VERSION "1"

NS_ :

BS_:

BU_: BATTERY BODY

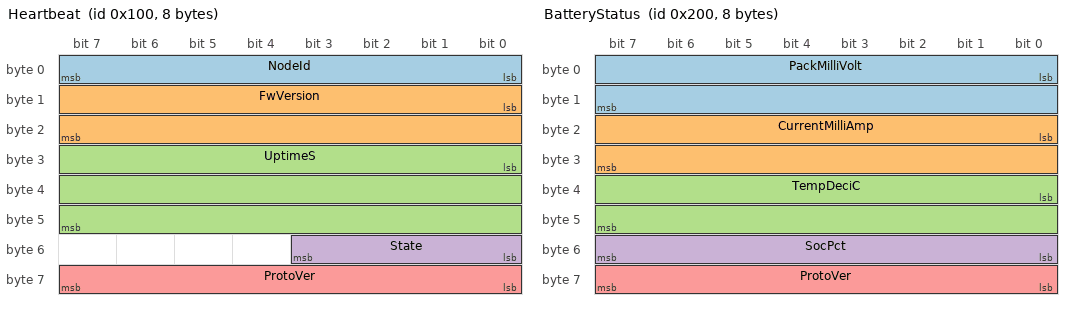
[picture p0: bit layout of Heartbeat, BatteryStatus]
BO_ 256 Heartbeat: 8 BATTERY
 SG_ NodeId : 0|8@1+ (1,0) [0|255] "" Vector__XXX
 SG_ FwVersion : 8|16@1+ (1,0) [0|65535] "" Vector__XXX
 SG_ UptimeS : 24|24@1+ (1,0) [0|16777215] "s" Vector__XXX
 SG_ State : 48|4@1+ (1,0) [0|15] "" Vector__XXX
 SG_ ProtoVer : 56|8@1+ (1,0) [0|255] "" Vector__XXX

BO_ 512 BatteryStatus: 8 BATTERY
 SG_ PackMilliVolt : 0|16@1+ (1,0) [0|65535] "mV" Vector__XXX
 SG_ CurrentMilliAmp : 16|16@1- (1,0) [-32768|32767] "mA" Vector__XXX
 SG_ TempDeciC : 32|16@1- (1,0) [-32768|32767] "0.1C" Vector__XXX
 SG_ SocPct : 48|8@1+ (1,0) [0|100] "%" Vector__XXX
 SG_ ProtoVer : 56|8@1+ (1,0) [0|255] "" Vector__XXX

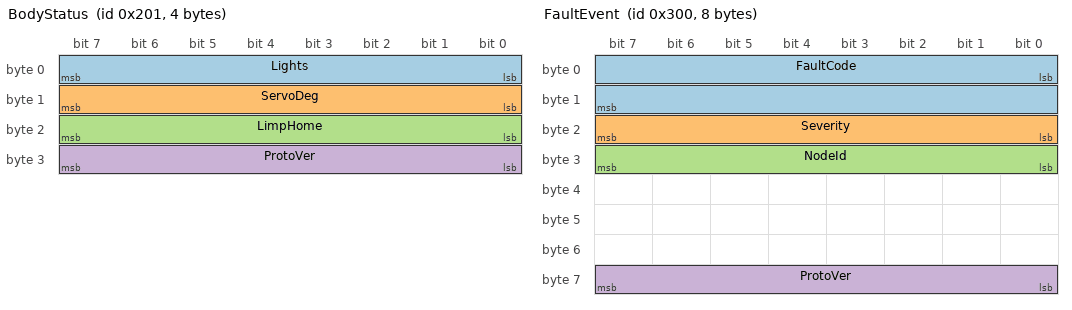
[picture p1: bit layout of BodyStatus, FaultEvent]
BO_ 513 BodyStatus: 4 BODY
 SG_ Lights : 0|8@1+ (1,0) [0|255] "" Vector__XXX
 SG_ ServoDeg : 8|8@1+ (1,0) [0|180] "deg" Vector__XXX
 SG_ LimpHome : 16|8@1+ (1,0) [0|1] "" Vector__XXX
 SG_ ProtoVer : 24|8@1+ (1,0) [0|255] "" Vector__XXX

BO_ 768 FaultEvent: 8 BATTERY
 SG_ FaultCode : 0|16@1+ (1,0) [0|65535] "" Vector__XXX
 SG_ Severity : 16|8@1+ (1,0) [0|3] "" Vector__XXX
 SG_ NodeId : 24|8@1+ (1,0) [0|255] "" Vector__XXX
 SG_ ProtoVer : 56|8@1+ (1,0) [0|255] "" Vector__XXX

CM_ BO_ 256 "10 Hz from every node, sent at 0x100 + NodeId (0x101 battery, 0x102 body) so two nodes never share an id. Sender column is nominal.";
CM_ SG_ 256 State "Node state, see VAL_ table";
CM_ BO_ 768 "On entering FAULT or SAFE, then once a second while latched";
CM_ SG_ 513 LimpHome "1 = body node is in limp-home";

VAL_ 256 State 0 "BOOT" 1 "NORMAL" 2 "WARNING" 3 "FAULT" 4 "SAFE" 5 "LIMP_HOME" ;
